AUTOSAR XML (schema 00048)
package /ComponentTypes
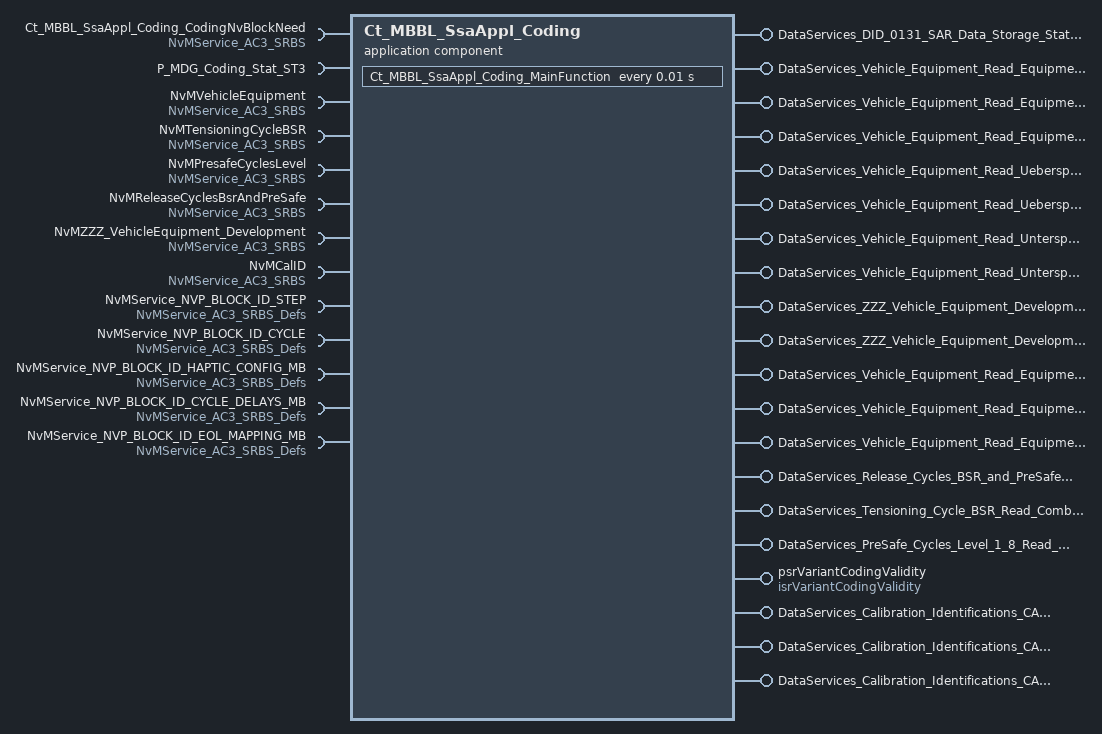
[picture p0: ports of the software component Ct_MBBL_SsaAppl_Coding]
  application sw component type Ct_MBBL_SsaAppl_Coding
    provide port DataServices_DID_0131_SAR_Data_Storage_Status: provided-interface=DataServices_DID_0131_SAR_Data_Storage_Status
      provided-com-specs:
        operation=ReadData, queue-length=1
        operation=ConditionCheckRead, queue-length=1
        operation=WriteData, queue-length=1
    require port Ct_MBBL_SsaAppl_Coding_CodingNvBlockNeed: required-com-specs=[GetErrorStatus, SetRamBlockStatus, ReadBlock, WriteBlock, InvalidateNvBlock, EraseBlock], required-interface=NvMService_AC3_SRBS
    require port P_MDG_Coding_Stat_ST3: mode-switch-receiver-com-spec=Coding_Status, required-interface=P_MDG_Coding_Stat_ST3
    7 x provide port:
      DataServices_Vehicle_Equipment_Read_Equipment_1: provided-interface=DataServices_Vehicle_Equipment_Read_Equipment_1
        provided-com-specs:
          operation=WriteData, queue-length=1
          operation=ConditionCheckRead, queue-length=1
          operation=ReadData, queue-length=1
      DataServices_Vehicle_Equipment_Read_Equipment_2: provided-interface=DataServices_Vehicle_Equipment_Read_Equipment_2
        provided-com-specs:
          operation=WriteData, queue-length=1
          operation=ConditionCheckRead, queue-length=1
          operation=ReadData, queue-length=1
      DataServices_Vehicle_Equipment_Read_Equipment_3: provided-interface=DataServices_Vehicle_Equipment_Read_Equipment_3
        provided-com-specs:
          operation=WriteData, queue-length=1
          operation=ConditionCheckRead, queue-length=1
          operation=ReadData, queue-length=1
      DataServices_Vehicle_Equipment_Read_Ueberspannungsabbruchschwelle: provided-interface=DataServices_Vehicle_Equipment_Read_Ueberspannungsabbruchschwelle
        provided-com-specs:
          operation=WriteData, queue-length=1
          operation=ConditionCheckRead, queue-length=1
          operation=ReadData, queue-length=1
      DataServices_Vehicle_Equipment_Read_Ueberspannungsbereichsschwelle: provided-interface=DataServices_Vehicle_Equipment_Read_Ueberspannungsbereichsschwelle
        provided-com-specs:
          operation=WriteData, queue-length=1
          operation=ConditionCheckRead, queue-length=1
          operation=ReadData, queue-length=1
      DataServices_Vehicle_Equipment_Read_Unterspannungsabbruchschwelle: provided-interface=DataServices_Vehicle_Equipment_Read_Unterspannungsabbruchschwelle
        provided-com-specs:
          operation=WriteData, queue-length=1
          operation=ConditionCheckRead, queue-length=1
          operation=ReadData, queue-length=1
      DataServices_Vehicle_Equipment_Read_Unterspannungsbereichsschwelle: provided-interface=DataServices_Vehicle_Equipment_Read_Unterspannungsbereichsschwelle
        provided-com-specs:
          operation=WriteData, queue-length=1
          operation=ConditionCheckRead, queue-length=1
          operation=ReadData, queue-length=1
    4 x require port, all with required-interface=NvMService_AC3_SRBS:
      NvMVehicleEquipment: required-com-specs=[WriteBlock, SetRamBlockStatus, ReadBlock, InvalidateNvBlock, GetErrorStatus, EraseBlock]
      NvMTensioningCycleBSR: required-com-specs=[EraseBlock, InvalidateNvBlock, WriteBlock, ReadBlock, SetRamBlockStatus, GetErrorStatus]
      NvMPresafeCyclesLevel: required-com-specs=[EraseBlock, InvalidateNvBlock, WriteBlock, ReadBlock, SetRamBlockStatus, GetErrorStatus]
      NvMReleaseCyclesBsrAndPreSafe: required-com-specs=[EraseBlock, InvalidateNvBlock, WriteBlock, ReadBlock, SetRamBlockStatus, GetErrorStatus]
    provide port DataServices_ZZZ_Vehicle_Equipment_Development_Read_Zykluszeit_Messtechnik: provided-interface=DataServices_ZZZ_Vehicle_Equipment_Development_Read_Zykluszeit_Messtechnik
      provided-com-specs:
        operation=WriteData, queue-length=1
        operation=ConditionCheckRead, queue-length=1
        operation=ReadData, queue-length=1
    provide port DataServices_ZZZ_Vehicle_Equipment_Development_Read_Bitfield: provided-interface=DataServices_ZZZ_Vehicle_Equipment_Development_Read_Bitfield
      provided-com-specs:
        operation=WriteData, queue-length=1
        operation=ConditionCheckRead, queue-length=1
        operation=ReadData, queue-length=1
    require port NvMZZZ_VehicleEquipment_Development: required-com-specs=[EraseBlock, InvalidateNvBlock, WriteBlock, ReadBlock, SetRamBlockStatus, GetErrorStatus], required-interface=NvMService_AC3_SRBS
    require port NvMCalID: required-com-specs=[EraseBlock, InvalidateNvBlock, WriteBlock, ReadBlock, SetRamBlockStatus, GetErrorStatus], required-interface=NvMService_AC3_SRBS
    6 x provide port:
      DataServices_Vehicle_Equipment_Read_Equipment_4: provided-interface=DataServices_Vehicle_Equipment_Read_Equipment_4
        provided-com-specs:
          operation=WriteData, queue-length=1
          operation=ConditionCheckRead, queue-length=1
          operation=ReadData, queue-length=1
      DataServices_Vehicle_Equipment_Read_Equipment_5: provided-interface=DataServices_Vehicle_Equipment_Read_Equipment_5
        provided-com-specs:
          operation=WriteData, queue-length=1
          operation=ConditionCheckRead, queue-length=1
          operation=ReadData, queue-length=1
      DataServices_Vehicle_Equipment_Read_Equipment_6: provided-interface=DataServices_Vehicle_Equipment_Read_Equipment_6
        provided-com-specs:
          operation=WriteData, queue-length=1
          operation=ConditionCheckRead, queue-length=1
          operation=ReadData, queue-length=1
      DataServices_Release_Cycles_BSR_and_PreSafe_Read_CombinedSignal: provided-interface=DataServices_Release_Cycles_BSR_and_PreSafe_Read_CombinedSignal
        provided-com-specs:
          operation=WriteData, queue-length=1
          operation=ConditionCheckRead, queue-length=1
          operation=ReadData, queue-length=1
      DataServices_Tensioning_Cycle_BSR_Read_CombinedSignal: provided-interface=DataServices_Tensioning_Cycle_BSR_Read_CombinedSignal
        provided-com-specs:
          operation=WriteData, queue-length=1
          operation=ConditionCheckRead, queue-length=1
          operation=ReadData, queue-length=1
      DataServices_PreSafe_Cycles_Level_1_8_Read_CombinedSignal: provided-interface=DataServices_PreSafe_Cycles_Level_1_8_Read_CombinedSignal
        provided-com-specs:
          operation=WriteData, queue-length=1
          operation=ConditionCheckRead, queue-length=1
          operation=ReadData, queue-length=1
    5 x require port, all with required-com-specs=[EraseBlock, InvalidateNvBlock, RestoreBlockDefaults, WriteBlock, ReadBlock, SetRamBlockStatus, GetErrorStatus], required-interface=NvMService_AC3_SRBS_Defs:
      NvMService_NVP_BLOCK_ID_STEP
      NvMService_NVP_BLOCK_ID_CYCLE
      NvMService_NVP_BLOCK_ID_HAPTIC_CONFIG_MB
      NvMService_NVP_BLOCK_ID_CYCLE_DELAYS_MB
      NvMService_NVP_BLOCK_ID_EOL_MAPPING_MB
    4 x provide port:
      psrVariantCodingValidity: provided-interface=isrVariantCodingValidity
        provided-com-specs:
          data-element=u8CodingValidity, init-value=constant-reference=APPLINIT_KB8_BOOLEAN_FALSE
          data-element=u8VehicleEquipValidity, init-value=constant-reference=APPLINIT_KB8_BOOLEAN_FALSE
      DataServices_Calibration_Identifications_CAL_ID_Write_Number_of_data_items: server-com-spec{operation=WriteData, queue-length=1}, provided-interface=DataServices_Calibration_Identifications_CAL_ID_Write_Number_of_data_items
      DataServices_Calibration_Identifications_CAL_ID_Write_Calibration_Identification: server-com-spec{operation=WriteData, queue-length=1}, provided-interface=DataServices_Calibration_Identifications_CAL_ID_Write_Calibration_Identification
      DataServices_Calibration_Identifications_CAL_ID_Read_Calibration_Identification: provided-interface=DataServices_Calibration_Identifications_CAL_ID_Read_Calibration_Identification
        provided-com-specs:
          operation=ConditionCheckRead, queue-length=1
          operation=ReadDataLength, queue-length=1
          operation=ReadData, queue-length=1
    behavior Ct_MBBL_SsaAppl_Coding_InternalBehavior
      6 x exclusive area:
        Coding_ExclusiveArea_VehicleEquipment
        Coding_ExclusiveArea_TensioningCycleBSR
        Coding_ExclusiveArea_PreSafeCyclesLevel
        Coding_ExclusiveArea_ReleaseCyclesBsrAndPreSafe
        Coding_ExclusiveArea_ZZZVehicleEquipmentDevelopment
        Coding_ExclusiveArea_CalID
      ar-typed-per-instance-memorys:
        14 x data, all with sw-calibration-access=READ-ONLY:
          PIM_CodingData: type=Idt_codingData
          PIM_OldCodingState: type=uint8
          VehicleEquipment: type=VehicleEquipment_StorageType
          VehicleEquipment_Mirror: type=VehicleEquipment_StorageType
          TensioningCycleBSR: type=TensioningCycleBSR_StorageType
          TensioningCycleBSR_Mirror: type=TensioningCycleBSR_StorageType
          PreSafeCyclesLevel: type=PreSafeCyclesLevel_StorageType
          PreSafeCyclesLevel_Mirror: type=PreSafeCyclesLevel_StorageType
          ReleaseCyclesBsrAndPreSafe: type=ReleaseCyclesBSRAndPresafe_StorageType
          ReleaseCyclesBsrAndPreSafe_Mirror: type=ReleaseCyclesBSRAndPresafe_StorageType
          ZZZ_VehicleEquipment_Development: type=ZZZ_VehicleEquipment_Development_StorageType
          ZZZ_VehicleEquipment_Development_Mirror: type=ZZZ_VehicleEquipment_Development_StorageType
          CalibrationID: type=CalibrationIdentifications_StorageType
          CalibrationID_Mirror: type=CalibrationIdentifications_StorageType
      init event Ct_MBBL_SsaAppl_Coding_InitEvent: start-on-event=Ct_MBBL_SsaAppl_Coding_Init
      timing event TMT_Ct_MBBL_SsaAppl_Coding_MainFunction: start-on-event=Ct_MBBL_SsaAppl_Coding_MainFunction, period=0.01
      53 x operation invoked event:
        OIT_DataServices_DID_0131_SAR_Data_Storage_Status_ConditionCheckRead_DataServices_DID_0131_SAR_Data_Storage_Status_Condi63BDADAD: start-on-event=DataServices_DID_0131_SAR_Data_Storage_Status_ConditionCheckRead, operation=DataServices_DID_0131_SAR_Data_Storage_Status.ConditionCheckRead
        OIT_DataServices_DID_0131_SAR_Data_Storage_Status_ReadData_DataServices_DID_0131_SAR_Data_Storage_Status_ReadData: start-on-event=DataServices_DID_0131_SAR_Data_Storage_Status_ReadData, operation=DataServices_DID_0131_SAR_Data_Storage_Status.ReadData
        OIT_DataServices_DID_0131_SAR_Data_Storage_Status_WriteData_DataServices_DID_0131_SAR_Data_Storage_Status_WriteData: start-on-event=DataServices_DID_0131_SAR_Data_Storage_Status_WriteData, operation=DataServices_DID_0131_SAR_Data_Storage_Status.WriteData
        OIT_DataServices_Vehicle_Equipment_Read_Equipment_1_DataServices_Vehicle_Equipment_Read_Equipment_1_ReadData: start-on-event=DataServices_Vehicle_Equipment_Read_Equipment_1_ReadData, operation=DataServices_Vehicle_Equipment_Read_Equipment_1.ReadData
        OIT_DataServices_Vehicle_Equipment_Read_Equipment_1_ConditionCheckRead_DataServices_Vehicle_Equipment_Read_Equipment_1_C14CB3DC8: start-on-event=DataServices_Vehicle_Equipment_Read_Equipment_1_ConditionCheckRead, operation=DataServices_Vehicle_Equipment_Read_Equipment_1.ConditionCheckRead
        OIT_DataServices_Vehicle_Equipment_Read_Equipment_2_ReadData_DataServices_Vehicle_Equipment_Read_Equipment_1_WriteData: start-on-event=DataServices_Vehicle_Equipment_Read_Equipment_1_WriteData, operation=DataServices_Vehicle_Equipment_Read_Equipment_1.WriteData
        OIT_DataServices_Vehicle_Equipment_Read_Equipment_2_ReadData_DataServices_Vehicle_Equipment_Read_Equipment_2_ReadData: start-on-event=DataServices_Vehicle_Equipment_Read_Equipment_2_ReadData, operation=DataServices_Vehicle_Equipment_Read_Equipment_2.ReadData
        OIT_DataServices_Vehicle_Equipment_Read_Equipment_2_ConditionCheckRead_DataServices_Vehicle_Equipment_Read_Equipment_2_C961432DF: start-on-event=DataServices_Vehicle_Equipment_Read_Equipment_2_ConditionCheckRead, operation=DataServices_Vehicle_Equipment_Read_Equipment_2.ConditionCheckRead
        OIT_DataServices_Vehicle_Equipment_Read_Equipment_2_WriteData_DataServices_Vehicle_Equipment_Read_Equipment_2_WriteData: start-on-event=DataServices_Vehicle_Equipment_Read_Equipment_2_WriteData, operation=DataServices_Vehicle_Equipment_Read_Equipment_2.WriteData
        OIT_DataServices_Vehicle_Equipment_Read_Equipment_3_ReadData_DataServices_Vehicle_Equipment_Read_Equipment_3_ReadData: start-on-event=DataServices_Vehicle_Equipment_Read_Equipment_3_ReadData, operation=DataServices_Vehicle_Equipment_Read_Equipment_3.ReadData
        OIT_DataServices_Vehicle_Equipment_Read_Equipment_3_WriteData_DataServices_Vehicle_Equipment_Read_Equipment_3_WriteData: start-on-event=DataServices_Vehicle_Equipment_Read_Equipment_3_WriteData, operation=DataServices_Vehicle_Equipment_Read_Equipment_3.WriteData
        OIT_DataServices_Vehicle_Equipment_Read_Equipment_3_ConditionCheckRead_DataServices_Vehicle_Equipment_Read_Equipment_3_C5E8E35ED: start-on-event=DataServices_Vehicle_Equipment_Read_Equipment_3_ConditionCheckRead, operation=DataServices_Vehicle_Equipment_Read_Equipment_3.ConditionCheckRead
        OIT_DataServices_Vehicle_Equipment_Read_Ueberspannungsabbruchschwelle_ReadData_DataServices_Vehicle_Equipment_Read_Ueber0452BCF1: start-on-event=DataServices_Vehicle_Equipment_Read_Uberspannungsabbruchschwelle_ReadData, operation=DataServices_Vehicle_Equipment_Read_Ueberspannungsabbruchschwelle.ReadData
        OIT_DataServices_Vehicle_Equipment_Read_Ueberspannungsabbruchschwelle_WriteData_DataServices_Vehicle_Equipment_Read_Uebe9DC76059: start-on-event=DataServices_Vehicle_Equipment_Read_Uberspannungsabbruchschwelle_WriteData, operation=DataServices_Vehicle_Equipment_Read_Ueberspannungsabbruchschwelle.WriteData
        OIT_DataServices_Vehicle_Equipment_Read_Ueberspannungsabbruchschwelle_ConditionCheckRead_DataServices_Vehicle_Equipment_6E705BEC: start-on-event=DataServices_Vehicle_Equipment_Read_Uberspannungsabbruchschwelle_ConditionCheckRead, operation=DataServices_Vehicle_Equipment_Read_Ueberspannungsabbruchschwelle.ConditionCheckRead
        OIT_DataServices_Vehicle_Equipment_Read_Ueberspannungsbereichsschwelle_ReadData_DataServices_Vehicle_Equipment_Read_Uebe9F6F3807: start-on-event=DataServices_Vehicle_Equipment_Read_Uberspannungsbereichsschwelle_ReadData, operation=DataServices_Vehicle_Equipment_Read_Ueberspannungsbereichsschwelle.ReadData
        OIT_DataServices_Vehicle_Equipment_Read_Ueberspannungsbereichsschwelle_ConditionCheckRead_DataServices_Vehicle_Equipment6A26849F: start-on-event=DataServices_Vehicle_Equipment_Read_Uberspannungsbereichsschwelle_ConditionCheckRead, operation=DataServices_Vehicle_Equipment_Read_Ueberspannungsbereichsschwelle.ConditionCheckRead
        OIT_DataServices_Vehicle_Equipment_Read_Ueberspannungsbereichsschwelle_WriteData_DataServices_Vehicle_Equipment_Read_UebD10E432E: start-on-event=DataServices_Vehicle_Equipment_Read_Uberspannungsbereichsschwelle_WriteData, operation=DataServices_Vehicle_Equipment_Read_Ueberspannungsbereichsschwelle.WriteData
        OIT_DataServices_Vehicle_Equipment_Read_Unterspannungsabbruchschwelle_ConditionCheckRead_DataServices_Vehicle_Equipment_B5FB7812: start-on-event=DataServices_Vehicle_Equipment_Read_Unterspannungsabbruchschwelle_ConditionCheckRead, operation=DataServices_Vehicle_Equipment_Read_Unterspannungsabbruchschwelle.ConditionCheckRead
        OIT_DataServices_Vehicle_Equipment_Read_Unterspannungsabbruchschwelle_ReadData_DataServices_Vehicle_Equipment_Read_UnterB069A23D: start-on-event=DataServices_Vehicle_Equipment_Read_Unterspannungsabbruchschwelle_ReadData, operation=DataServices_Vehicle_Equipment_Read_Unterspannungsabbruchschwelle.ReadData
        OIT_DataServices_Vehicle_Equipment_Read_Unterspannungsabbruchschwelle_WriteData_DataServices_Vehicle_Equipment_Read_UnteC8D2111C: start-on-event=DataServices_Vehicle_Equipment_Read_Unterspannungsabbruchschwelle_WriteData, operation=DataServices_Vehicle_Equipment_Read_Unterspannungsabbruchschwelle.WriteData
        OIT_DataServices_Vehicle_Equipment_Read_Unterspannungsbereichsschwelle_ConditionCheckRead_DataServices_Vehicle_EquipmentB436927A: start-on-event=DataServices_Vehicle_Equipment_Read_Unterspannungsbereichsschwelle_ConditionCheckRead, operation=DataServices_Vehicle_Equipment_Read_Unterspannungsbereichsschwelle.ConditionCheckRead
        OIT_DataServices_Vehicle_Equipment_Read_Unterspannungsbereichsschwelle_ReadData_DataServices_Vehicle_Equipment_Read_UnteCA7A4942: start-on-event=DataServices_Vehicle_Equipment_Read_Unterspannungsbereichsschwelle_ReadData, operation=DataServices_Vehicle_Equipment_Read_Unterspannungsbereichsschwelle.ReadData
        OIT_DataServices_Vehicle_Equipment_Read_Unterspannungsbereichsschwelle_WriteData_DataServices_Vehicle_Equipment_Read_Unt801EF5D4: start-on-event=DataServices_Vehicle_Equipment_Read_Unterspannungsbereichsschwelle_WriteData, operation=DataServices_Vehicle_Equipment_Read_Unterspannungsbereichsschwelle.WriteData
        OIT_Runnable_DataServices_ZZZ_Vehicle_Equipment_Development_Read_Bitfield_ConditionCheckRead: start-on-event=DataServices_ZZZ_Vehicle_Equipment_Development_Read_Bitfield_ConditionCheckRead, operation=DataServices_ZZZ_Vehicle_Equipment_Development_Read_Bitfield.ConditionCheckRead
        OIT_DataServices_ZZZ_Vehicle_Equipment_Development_Read_Bitfield_ReadData_DataServices_ZZZ_Vehicle_Equipment_DevelopmentD2900FC8: start-on-event=DataServices_ZZZ_Vehicle_Equipment_Development_Read_Bitfield_ReadData, operation=DataServices_ZZZ_Vehicle_Equipment_Development_Read_Bitfield.ReadData
        OIT_DataServices_ZZZ_Vehicle_Equipment_Development_Read_Bitfield_WriteData_DataServices_ZZZ_Vehicle_Equipment_Developmen0AE26214: start-on-event=DataServices_ZZZ_Vehicle_Equipment_Development_Read_Bitfield_WriteData, operation=DataServices_ZZZ_Vehicle_Equipment_Development_Read_Bitfield.WriteData
        OIT_Runnable_DataServices_ZZZ_Vehicle_Equipment_Development_Read_Zykluszeit_Messtechnik_ConditionCheckRead: start-on-event=DataServices_ZZZ_Vehicle_Equipment_Development_Read_Zykluszeit_Messtechnik_ConditionCheckRead, operation=DataServices_ZZZ_Vehicle_Equipment_Development_Read_Zykluszeit_Messtechnik.ConditionCheckRead
        OIT_DataServices_ZZZ_Vehicle_Equipment_Development_Read_Zykluszeit_Messtechnik_ReadData_DataServices_ZZZ_Vehicle_Equipme987B52E0: start-on-event=DataServices_ZZZ_Vehicle_Equipment_Development_Read_Zykluszeit_Messtechnik_ReadData, operation=DataServices_ZZZ_Vehicle_Equipment_Development_Read_Zykluszeit_Messtechnik.ReadData
        OIT_DataServices_ZZZ_Vehicle_Equipment_Development_Read_Zykluszeit_Messtechnik_WriteData_DataServices_ZZZ_Vehicle_Equipm7787BDE0: start-on-event=DataServices_ZZZ_Vehicle_Equipment_Development_Read_Zykluszeit_Messtechnik_WriteData, operation=DataServices_ZZZ_Vehicle_Equipment_Development_Read_Zykluszeit_Messtechnik.WriteData
        OIT_DataServices_PreSafe_Cycles_Level_1_8_CombinedSignal_ConditionCheckRead_DataServices_PreSafe_Cycles_Level_1_8_Read_C2C1D2605: start-on-event=DataServices_PreSafe_Cycles_Level_1_8_CombinedSignal_ConditionCheckRead, operation=DataServices_PreSafe_Cycles_Level_1_8_Read_CombinedSignal.ConditionCheckRead
        OIT_DataServices_PreSafe_Cycles_Level_1_8_CombinedSignal_ReadData_DataServices_PreSafe_Cycles_Level_1_8_Read_CombinedSig60CB48E7: start-on-event=DataServices_PreSafe_Cycles_Level_1_8_CombinedSignal_ReadData, operation=DataServices_PreSafe_Cycles_Level_1_8_Read_CombinedSignal.ReadData
        OIT_DataServices_PreSafe_Cycles_Level_1_8_CombinedSignal_WriteData_DataServices_PreSafe_Cycles_Level_1_8_Read_CombinedSi84CC309E: start-on-event=DataServices_PreSafe_Cycles_Level_1_8_CombinedSignal_WriteData, operation=DataServices_PreSafe_Cycles_Level_1_8_Read_CombinedSignal.WriteData
        OIT_DataServices_Release_Cycles_BSR_and_PreSafe_CombinedSignal_ConditionCheckRead_DataServices_Release_Cycles_BSR_and_Pr3FAC3745: start-on-event=DataServices_Release_Cycles_BSR_and_PreSafe_CombinedSignal_ConditionCheckRead, operation=DataServices_Release_Cycles_BSR_and_PreSafe_Read_CombinedSignal.ConditionCheckRead
        OIT_DataServices_Release_Cycles_BSR_and_PreSafe_CombinedSignal_ReadData_DataServices_Release_Cycles_BSR_and_PreSafe_Read10383739: start-on-event=DataServices_Release_Cycles_BSR_and_PreSafe_CombinedSignal_ReadData, operation=DataServices_Release_Cycles_BSR_and_PreSafe_Read_CombinedSignal.ReadData
        OIT_DataServices_Release_Cycles_BSR_and_PreSafe_CombinedSignal_ReadData_WriteData_DataServices_Release_Cycles_BSR_and_PrFF86B5A8: start-on-event=DataServices_Release_Cycles_BSR_and_PreSafe_CombinedSignal_ReadData_WriteData, operation=DataServices_Release_Cycles_BSR_and_PreSafe_Read_CombinedSignal.WriteData
        OIT_DataServices_Tensioning_Cycle_BSR_CombinedSigna_ConditionCheckRead_DataServices_Tensioning_Cycle_BSR_Read_CombinedSi3413FD76: start-on-event=DataServices_Tensioning_Cycle_BSR_CombinedSignal_ConditionCheckRead, operation=DataServices_Tensioning_Cycle_BSR_Read_CombinedSignal.ConditionCheckRead
        OIT_DataServices_Tensioning_Cycle_BSR_CombinedSigna_ReadData_DataServices_Tensioning_Cycle_BSR_Read_CombinedSignal_ReadData: start-on-event=DataServices_Tensioning_Cycle_BSR_CombinedSignal_ReadData, operation=DataServices_Tensioning_Cycle_BSR_Read_CombinedSignal.ReadData
        OIT_DataServices_Tensioning_Cycle_BSR_CombinedSigna_WriteData_DataServices_Tensioning_Cycle_BSR_Read_CombinedSignal_WriteData: start-on-event=DataServices_Tensioning_Cycle_BSR_CombinedSignal_WriteData, operation=DataServices_Tensioning_Cycle_BSR_Read_CombinedSignal.WriteData
        OIT_DataServices_Vehicle_Equipment_Read_Equipment_4_ConditionCheckRead_DataServices_Vehicle_Equipment_Read_Equipment_4_C48DB2AB0: start-on-event=DataServices_Vehicle_Equipment_Read_Equipment_4_ConditionCheckRead, operation=DataServices_Vehicle_Equipment_Read_Equipment_4.ConditionCheckRead
        OIT_DataServices_Vehicle_Equipment_Read_Equipment_4_ReadData_DataServices_Vehicle_Equipment_Read_Equipment_4_ReadData: start-on-event=DataServices_Vehicle_Equipment_Read_Equipment_4_ReadData, operation=DataServices_Vehicle_Equipment_Read_Equipment_4.ReadData
        OIT_DataServices_Vehicle_Equipment_Read_Equipment_4_WriteData_DataServices_Vehicle_Equipment_Read_Equipment_4_WriteData: start-on-event=DataServices_Vehicle_Equipment_Read_Equipment_4_WriteData, operation=DataServices_Vehicle_Equipment_Read_Equipment_4.WriteData
        OIT_DataServices_Vehicle_Equipment_Read_Equipment_5_ConditionCheckRead_DataServices_Vehicle_Equipment_Read_Equipment_5_C80412D82: start-on-event=DataServices_Vehicle_Equipment_Read_Equipment_5_ConditionCheckRead, operation=DataServices_Vehicle_Equipment_Read_Equipment_5.ConditionCheckRead
        OIT_DataServices_Vehicle_Equipment_Read_Equipment_5_ReadData_DataServices_Vehicle_Equipment_Read_Equipment_5_ReadData: start-on-event=DataServices_Vehicle_Equipment_Read_Equipment_5_ReadData, operation=DataServices_Vehicle_Equipment_Read_Equipment_5.ReadData
        OIT_DataServices_Vehicle_Equipment_Read_Equipment_5_WriteData_DataServices_Vehicle_Equipment_Read_Equipment_5_WriteData: start-on-event=DataServices_Vehicle_Equipment_Read_Equipment_5_WriteData, operation=DataServices_Vehicle_Equipment_Read_Equipment_5.WriteData
        OIT_DataServices_Vehicle_Equipment_Read_Equipment_6_ConditionCheckRead_DataServices_Vehicle_Equipment_Read_Equipment_6_C029E2295: start-on-event=DataServices_Vehicle_Equipment_Read_Equipment_6_ConditionCheckRead, operation=DataServices_Vehicle_Equipment_Read_Equipment_6.ConditionCheckRead
        OIT_DataServices_Vehicle_Equipment_Read_Equipment_6_ReadData_DataServices_Vehicle_Equipment_Read_Equipment_6_ReadData: start-on-event=DataServices_Vehicle_Equipment_Read_Equipment_6_ReadData, operation=DataServices_Vehicle_Equipment_Read_Equipment_6.ReadData
        OIT_DataServices_Vehicle_Equipment_Read_Equipment_6_WriteData_DataServices_Vehicle_Equipment_Read_Equipment_6_WriteData: start-on-event=DataServices_Vehicle_Equipment_Read_Equipment_6_WriteData, operation=DataServices_Vehicle_Equipment_Read_Equipment_6.WriteData
        OIT_DataServices_Calibration_Identifications_CAL_ID_Read_CombinedDataElement_ConditionCheckRead_DataServices_Calibration4AA24625: start-on-event=DataServices_Calibration_Identifications_CAL_ID_Read_CombinedDataElement_ConditionCheckRead, operation=DataServices_Calibration_Identifications_CAL_ID_Read_Calibration_Identification.ConditionCheckRead
        OIT_DataServices_Calibration_Identifications_CAL_ID_Read_CombinedDataElement_ReadData_DataServices_Calibration_Identific0514BE4B: start-on-event=DataServices_Calibration_Identifications_CAL_ID_Read_CombinedDataElement_ReadData, operation=DataServices_Calibration_Identifications_CAL_ID_Read_Calibration_Identification.ReadData
        OIT_DataServices_Calibration_Identifications_CAL_ID_Read_CombinedDataElement_ReadDataLength_DataServices_Calibration_Ide7B1530A1: start-on-event=DataServices_Calibration_Identifications_CAL_ID_Read_CombinedDataElement_ReadDataLength, operation=DataServices_Calibration_Identifications_CAL_ID_Read_Calibration_Identification.ReadDataLength
        OIT_DataServices_Calibration_Identifications_CAL_ID_Read_CombinedDataElement_WriteData_DataServices_Calibration_Identifi4416B2B4: start-on-event=DataServices_Calibration_Identifications_CAL_ID_Write_CombinedDataElement_WriteData, operation=DataServices_Calibration_Identifications_CAL_ID_Write_Calibration_Identification.WriteData
        OIT_DataServices_Calibration_Identifications_CAL_ID_Write_Number_of_data_items_DataServices_Calibration_Identifications_21BB6B26: start-on-event=DataServices_Calibration_Identifications_CAL_ID_Write_Number_of_data_items, operation=DataServices_Calibration_Identifications_CAL_ID_Write_Number_of_data_items.WriteData
      55 x runnable:
        Ct_MBBL_SsaAppl_Coding_Init
          data-send-points:
            access SEND_psrVariantCodingValidity_u8CodingValidity: accessed-variable=psrVariantCodingValidity.u8CodingValidity
            access SEND_psrVariantCodingValidity_u8VehicleEquipValidity: accessed-variable=psrVariantCodingValidity.u8VehicleEquipValidity
          10 x sync call:
            SC_NvMService_NVP_BLOCK_ID_CYCLE_GetErrorStatus: operation=NvMService_NVP_BLOCK_ID_CYCLE.GetErrorStatus
            SC_NvMService_NVP_BLOCK_ID_CYCLE_WriteBlock: operation=NvMService_NVP_BLOCK_ID_CYCLE.WriteBlock
            SC_NvMService_NVP_BLOCK_ID_CYCLE_DELAYS_MB_GetErrorStatus: operation=NvMService_NVP_BLOCK_ID_CYCLE_DELAYS_MB.GetErrorStatus
            SC_NvMService_NVP_BLOCK_ID_CYCLE_DELAYS_MB_WriteBlock: operation=NvMService_NVP_BLOCK_ID_CYCLE_DELAYS_MB.WriteBlock
            SC_NvMService_NVP_BLOCK_ID_EOL_MAPPING_MB_GetErrorStatus: operation=NvMService_NVP_BLOCK_ID_EOL_MAPPING_MB.GetErrorStatus
            SC_NvMService_NVP_BLOCK_ID_EOL_MAPPING_MB_WriteBlock: operation=NvMService_NVP_BLOCK_ID_EOL_MAPPING_MB.WriteBlock
            SC_NvMService_NVP_BLOCK_ID_HAPTIC_CONFIG_MB_GetErrorStatus: operation=NvMService_NVP_BLOCK_ID_HAPTIC_CONFIG_MB.GetErrorStatus
            SC_NvMService_NVP_BLOCK_ID_HAPTIC_CONFIG_MB_WriteBlock: operation=NvMService_NVP_BLOCK_ID_HAPTIC_CONFIG_MB.WriteBlock
            SC_NvMService_NVP_BLOCK_ID_STEP_GetErrorStatus: operation=NvMService_NVP_BLOCK_ID_STEP.GetErrorStatus
            SC_NvMService_NVP_BLOCK_ID_STEP_WriteBlock: operation=NvMService_NVP_BLOCK_ID_STEP.WriteBlock
        Ct_MBBL_SsaAppl_Coding_MainFunction: can-enter-exclusive-area=[Coding_ExclusiveArea_VehicleEquipment, Coding_ExclusiveArea_TensioningCycleBSR, Coding_ExclusiveArea_PreSafeCyclesLevel, Coding_ExclusiveArea_ReleaseCyclesBsrAndPreSafe, Coding_ExclusiveArea_ZZZVehicleEquipmentDevelopment, Coding_ExclusiveArea_CalID], mode-access-point=P_MDG_Coding_Stat_ST3.Coding_Status
          19 x sync call:
            SC_Ct_MBBL_SsaAppl_Coding_CodingNvBlockNeed_GetErrorStatus: operation=Ct_MBBL_SsaAppl_Coding_CodingNvBlockNeed.GetErrorStatus
            SC_NvMVehicleEquipment_GetErrorStatus: operation=NvMVehicleEquipment.GetErrorStatus
            SC_NvMVehicleEquipment_ReadBlock: operation=NvMVehicleEquipment.ReadBlock
            SC_NvMVehicleEquipment_WriteBlock: operation=NvMVehicleEquipment.WriteBlock
            SC_NvMTensioningCycleBSR_GetErrorStatus: operation=NvMTensioningCycleBSR.GetErrorStatus
            SC_NvMTensioningCycleBSR_ReadBlock: operation=NvMTensioningCycleBSR.ReadBlock
            SC_NvMTensioningCycleBSR_WriteBlock: operation=NvMTensioningCycleBSR.WriteBlock
            SC_NvMPresafeCyclesLevel_GetErrorStatus: operation=NvMPresafeCyclesLevel.GetErrorStatus
            SC_NvMPresafeCyclesLevel_ReadBlock: operation=NvMPresafeCyclesLevel.ReadBlock
            SC_NvMPresafeCyclesLevel_WriteBlock: operation=NvMPresafeCyclesLevel.WriteBlock
            SC_NvMReleaseCyclesBsrAndPreSafe_GetErrorStatus: operation=NvMReleaseCyclesBsrAndPreSafe.GetErrorStatus
            SC_NvMReleaseCyclesBsrAndPreSafe_ReadBlock: operation=NvMReleaseCyclesBsrAndPreSafe.ReadBlock
            SC_NvMReleaseCyclesBsrAndPreSafe_WriteBlock: operation=NvMReleaseCyclesBsrAndPreSafe.WriteBlock
            SC_NvMZZZ_VehicleEquipment_Development_GetErrorStatus: operation=NvMZZZ_VehicleEquipment_Development.GetErrorStatus
            SC_NvMZZZ_VehicleEquipment_Development_ReadBlock: operation=NvMZZZ_VehicleEquipment_Development.ReadBlock
            SC_NvMZZZ_VehicleEquipment_Development_WriteBlock: operation=NvMZZZ_VehicleEquipment_Development.WriteBlock
            SC_NvMCalID_GetErrorStatus: operation=NvMCalID.GetErrorStatus
            SC_NvMCalID_ReadBlock: operation=NvMCalID.ReadBlock
            SC_NvMCalID_WriteBlock: operation=NvMCalID.WriteBlock
        DataServices_DID_0131_SAR_Data_Storage_Status_ConditionCheckRead
        DataServices_DID_0131_SAR_Data_Storage_Status_ReadData
        DataServices_DID_0131_SAR_Data_Storage_Status_WriteData
        DataServices_Vehicle_Equipment_Read_Equipment_1_ReadData: can-enter-exclusive-area=Coding_ExclusiveArea_VehicleEquipment
        DataServices_Vehicle_Equipment_Read_Equipment_1_ConditionCheckRead: can-enter-exclusive-area=Coding_ExclusiveArea_VehicleEquipment
        DataServices_Vehicle_Equipment_Read_Equipment_1_WriteData: can-enter-exclusive-area=Coding_ExclusiveArea_VehicleEquipment
        DataServices_Vehicle_Equipment_Read_Equipment_2_ReadData: can-enter-exclusive-area=Coding_ExclusiveArea_VehicleEquipment
        DataServices_Vehicle_Equipment_Read_Equipment_2_ConditionCheckRead: can-enter-exclusive-area=Coding_ExclusiveArea_VehicleEquipment
        DataServices_Vehicle_Equipment_Read_Equipment_2_WriteData: can-enter-exclusive-area=Coding_ExclusiveArea_VehicleEquipment
        DataServices_Vehicle_Equipment_Read_Equipment_3_ReadData: can-enter-exclusive-area=Coding_ExclusiveArea_VehicleEquipment
        DataServices_Vehicle_Equipment_Read_Equipment_3_WriteData: can-enter-exclusive-area=Coding_ExclusiveArea_VehicleEquipment
        DataServices_Vehicle_Equipment_Read_Equipment_3_ConditionCheckRead: can-enter-exclusive-area=Coding_ExclusiveArea_VehicleEquipment
        DataServices_Vehicle_Equipment_Read_Uberspannungsabbruchschwelle_ReadData: can-enter-exclusive-area=Coding_ExclusiveArea_VehicleEquipment
        DataServices_Vehicle_Equipment_Read_Uberspannungsabbruchschwelle_WriteData: can-enter-exclusive-area=Coding_ExclusiveArea_VehicleEquipment
        DataServices_Vehicle_Equipment_Read_Uberspannungsabbruchschwelle_ConditionCheckRead: can-enter-exclusive-area=Coding_ExclusiveArea_VehicleEquipment
        DataServices_Vehicle_Equipment_Read_Uberspannungsbereichsschwelle_ReadData: can-enter-exclusive-area=Coding_ExclusiveArea_VehicleEquipment
        DataServices_Vehicle_Equipment_Read_Uberspannungsbereichsschwelle_ConditionCheckRead: can-enter-exclusive-area=Coding_ExclusiveArea_VehicleEquipment
        DataServices_Vehicle_Equipment_Read_Uberspannungsbereichsschwelle_WriteData: can-enter-exclusive-area=Coding_ExclusiveArea_VehicleEquipment
        DataServices_Vehicle_Equipment_Read_Unterspannungsabbruchschwelle_ConditionCheckRead: can-enter-exclusive-area=Coding_ExclusiveArea_VehicleEquipment
        DataServices_Vehicle_Equipment_Read_Unterspannungsabbruchschwelle_ReadData: can-enter-exclusive-area=Coding_ExclusiveArea_VehicleEquipment
        DataServices_Vehicle_Equipment_Read_Unterspannungsabbruchschwelle_WriteData: can-enter-exclusive-area=Coding_ExclusiveArea_VehicleEquipment
        DataServices_Vehicle_Equipment_Read_Unterspannungsbereichsschwelle_ConditionCheckRead: can-enter-exclusive-area=Coding_ExclusiveArea_VehicleEquipment
        DataServices_Vehicle_Equipment_Read_Unterspannungsbereichsschwelle_ReadData: can-enter-exclusive-area=Coding_ExclusiveArea_VehicleEquipment
        DataServices_Vehicle_Equipment_Read_Unterspannungsbereichsschwelle_WriteData: can-enter-exclusive-area=Coding_ExclusiveArea_VehicleEquipment
        DataServices_ZZZ_Vehicle_Equipment_Development_Read_Bitfield_ConditionCheckRead: can-enter-exclusive-area=Coding_ExclusiveArea_ZZZVehicleEquipmentDevelopment
        DataServices_ZZZ_Vehicle_Equipment_Development_Read_Bitfield_ReadData: can-enter-exclusive-area=Coding_ExclusiveArea_ZZZVehicleEquipmentDevelopment
        DataServices_ZZZ_Vehicle_Equipment_Development_Read_Bitfield_WriteData: can-enter-exclusive-area=Coding_ExclusiveArea_ZZZVehicleEquipmentDevelopment
        DataServices_ZZZ_Vehicle_Equipment_Development_Read_Zykluszeit_Messtechnik_ConditionCheckRead: can-enter-exclusive-area=Coding_ExclusiveArea_ZZZVehicleEquipmentDevelopment
        DataServices_ZZZ_Vehicle_Equipment_Development_Read_Zykluszeit_Messtechnik_ReadData: can-enter-exclusive-area=Coding_ExclusiveArea_ZZZVehicleEquipmentDevelopment
        DataServices_ZZZ_Vehicle_Equipment_Development_Read_Zykluszeit_Messtechnik_WriteData: can-enter-exclusive-area=Coding_ExclusiveArea_ZZZVehicleEquipmentDevelopment
        DataServices_Calibration_Identifications_CAL_ID_Read_CombinedDataElement_ConditionCheckRead: can-enter-exclusive-area=Coding_ExclusiveArea_CalID
        DataServices_Calibration_Identifications_CAL_ID_Read_CombinedDataElement_ReadData: can-enter-exclusive-area=Coding_ExclusiveArea_CalID
        DataServices_Calibration_Identifications_CAL_ID_Read_CombinedDataElement_ReadDataLength: can-enter-exclusive-area=Coding_ExclusiveArea_CalID
        DataServices_Calibration_Identifications_CAL_ID_Write_CombinedDataElement_WriteData: can-enter-exclusive-area=Coding_ExclusiveArea_CalID
        DataServices_Vehicle_Equipment_Read_Equipment_4_ConditionCheckRead
        DataServices_Vehicle_Equipment_Read_Equipment_4_ReadData
        DataServices_Vehicle_Equipment_Read_Equipment_4_WriteData
        DataServices_Vehicle_Equipment_Read_Equipment_5_ConditionCheckRead
        DataServices_Vehicle_Equipment_Read_Equipment_5_ReadData
        DataServices_Vehicle_Equipment_Read_Equipment_5_WriteData
        DataServices_Vehicle_Equipment_Read_Equipment_6_ConditionCheckRead
        DataServices_Vehicle_Equipment_Read_Equipment_6_ReadData
        DataServices_Vehicle_Equipment_Read_Equipment_6_WriteData
        DataServices_Tensioning_Cycle_BSR_CombinedSignal_ReadData
        DataServices_Tensioning_Cycle_BSR_CombinedSignal_WriteData
        DataServices_Tensioning_Cycle_BSR_CombinedSignal_ConditionCheckRead
        DataServices_Release_Cycles_BSR_and_PreSafe_CombinedSignal_ReadData
        DataServices_Release_Cycles_BSR_and_PreSafe_CombinedSignal_ConditionCheckRead
        DataServices_Release_Cycles_BSR_and_PreSafe_CombinedSignal_ReadData_WriteData
        DataServices_PreSafe_Cycles_Level_1_8_CombinedSignal_ReadData
        DataServices_PreSafe_Cycles_Level_1_8_CombinedSignal_ConditionCheckRead
        DataServices_PreSafe_Cycles_Level_1_8_CombinedSignal_WriteData
        DataServices_Calibration_Identifications_CAL_ID_Write_Number_of_data_items
      7 x swc service dependency:
        NvBlockNeed_CodingData
          assigned-datas:
            role=ramBlock, used-data-element=PIM_CodingData
            role=defaultValue, used-parameter-element=Cal_CodingDataInit
            role=defaultValue, used-parameter-element=Cal_CodingDataInit
          service-needs:
            nv block needs NvBlockNeed_CodingData: n-data-sets=0, ram-block-status-control=API, reliability=NO-PROTECTION, restore-at-start=false, store-at-shutdown=false
        NvmCoding_CurrentVehicleEquipment: assigned-datas=role-based-data-assignment={role=ramBlock, used-data-element=VehicleEquipment}
          service-needs:
            nv block needs NvmCoding_CurrentVehicleEquipment: n-data-sets=0, ram-block-status-control=API, reliability=NO-PROTECTION, restore-at-start=false, store-at-shutdown=false
        NvmCoding_TensioningCycleBSR: assigned-datas=role-based-data-assignment={role=ramBlock, used-data-element=TensioningCycleBSR}
          service-needs:
            nv block needs NvmCoding_TensioningCycleBSR: ram-block-status-control=API, restore-at-start=true, store-at-shutdown=false
        NvmCoding_PreSafeCyclesLevel: assigned-datas=[{role=ramBlock, used-data-element=PreSafeCyclesLevel}, role=defaultValue]
          service-needs:
            nv block needs NvmCoding_PreSafeCyclesLevel: ram-block-status-control=API, restore-at-start=true, store-at-shutdown=false
        NvmCoding_ReleaseCyclesBsrAndPreSafe: assigned-datas=role-based-data-assignment={role=ramBlock, used-data-element=ReleaseCyclesBsrAndPreSafe}
          service-needs:
            nv block needs NvmCoding_ReleaseCyclesBsrAndPreSafe: ram-block-status-control=API, restore-at-start=true, store-at-shutdown=false
        NvmCoding_ZZZVehicleEquipmentDevelopment: assigned-datas=role-based-data-assignment={role=ramBlock, used-data-element=ZZZ_VehicleEquipment_Development}
          service-needs:
            nv block needs NvmCoding_ZZZVehicleEquipmentDevelopment: ram-block-status-control=API, restore-at-start=true, store-at-shutdown=false
        NvmCoding_CalibrationID: assigned-datas=role-based-data-assignment={role=ramBlock, used-data-element=CalibrationID}
          service-needs:
            nv block needs NvmCoding_CalibrationID: ram-block-status-control=API, restore-at-start=true, store-at-shutdown=false
      shared-parameters:
        parameter data prototype Cal_CodingDataInit: sw-calibration-access=READ-WRITE, type=Idt_codingData, init-value=constant-reference=Const_CodingDataInit
  swc implementation Ct_MBBL_SsaAppl_Coding_Implementation: behavior=Ct_MBBL_SsaAppl_Coding_InternalBehavior
    code-descriptors:
      code Default: artifact-descriptors=autosar-engineering-object=category=SWSRC
